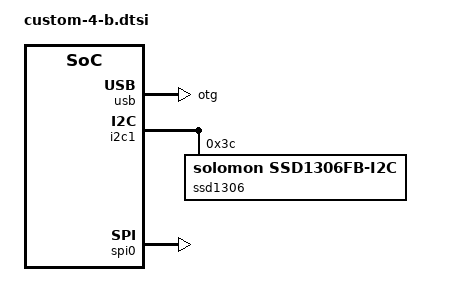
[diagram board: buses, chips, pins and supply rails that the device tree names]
&usb {
	compatible = "brcm,bcm2835-usb";
	dr_mode = "otg";
	g-np-tx-fifo-size = <32>;
	g-rx-fifo-size = <558>;
	g-tx-fifo-size = <512 512 512 512 512 256 256>;
	status = "okay";
};

&i2c1 {
    status = "okay";
    pinctrl-names = "default";
    pinctrl-0 = <&i2c1_pins>;

	#address-cells = <1>;
	#size-cells = <0>;

	ssd1306: oled@3c{
		compatible = "solomon,ssd1306fb-i2c";
		reg = <0x3c>;
		solomon,width = <128>;
		solomon,height = <64>;
		solomon,page-offset = <0>;
		solomon,com-invdir = "true";
	};
};

&spi0 {
	status = "okay";
};

&gpio {
	uart0_pins: uart0_pins {
		brcm,pins = <32 33 30 31>;
		brcm,function = <BCM2835_FSEL_ALT3>;
		brcm,pull = <0 2 2 0>;
	};

	uart1_pins: uart1_pins {
		brcm,pins = <14 15>;
		brcm,function = <2>; /* alt5 */
		brcm,pull = <0 2>;
	};
};
